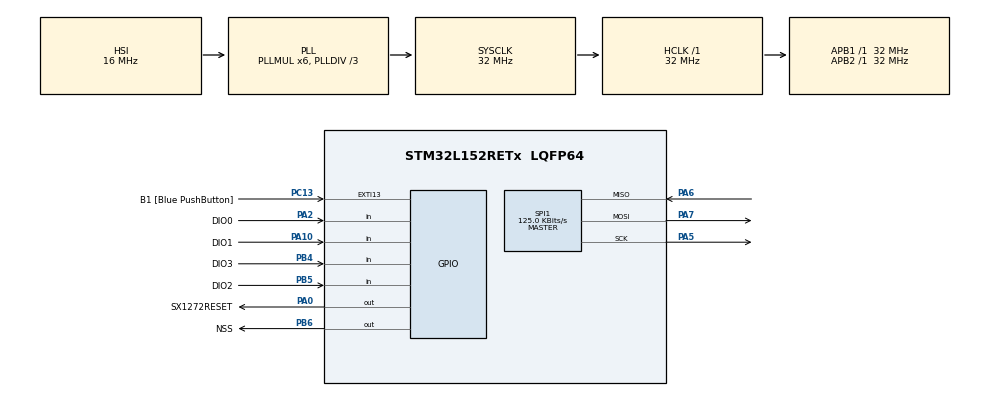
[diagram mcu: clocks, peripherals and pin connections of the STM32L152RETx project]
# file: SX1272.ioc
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Mcu.Family=STM32L1
Mcu.Name=STM32L152RETx
Mcu.Package=LQFP64
NVIC.PriorityGroup=NVIC_PRIORITYGROUP_0
NVIC.TIM11_IRQn=true\:0\:0\:false\:false\:true\:true\:true
PA0-WKUP1.GPIO_Label=SX1272RESET
PA0-WKUP1.Signal=GPIO_Output
PA10.GPIO_Label=DIO1
PA10.Signal=GPIO_Input
PA13.GPIO_Label=TMS
PA13.Mode=Serial_Wire
PA13.Signal=SYS_JTMS-SWDIO
PA14.GPIO_Label=TCK
PA14.Mode=Serial_Wire
PA14.Signal=SYS_JTCK-SWCLK
PA2.GPIO_Label=DIO0
PA2.Signal=GPIO_Input
PA5.Mode=Full_Duplex_Master
PA5.Signal=SPI1_SCK
PA6.Mode=Full_Duplex_Master
PA6.Signal=SPI1_MISO
PA7.Mode=Full_Duplex_Master
PA7.Signal=SPI1_MOSI
PB3.GPIO_Label=SWO
PB3.Signal=SYS_JTDO-TRACESWO
PB4.GPIO_Label=DIO3
PB4.Signal=GPIO_Input
PB5.GPIO_Label=DIO2
PB5.Signal=GPIO_Input
PB6.GPIO_Label=NSS
PB6.Signal=GPIO_Output
PC13-WKUP2.GPIO_Label=B1 [Blue PushButton]
PC13-WKUP2.Signal=GPXTI13
PC14-OSC32_IN.Mode=LSE-External-Oscillator
PC14-OSC32_IN.Signal=RCC_OSC32_IN
PC15-OSC32_OUT.Mode=LSE-External-Oscillator
PC15-OSC32_OUT.Signal=RCC_OSC32_OUT
PH0-OSC_IN.Mode=HSE-External-Clock-Source
PH0-OSC_IN.Signal=RCC_OSC_IN
PH1-OSC_OUT.Signal=RCC_OSC_OUT
ProjectManager.HeapSize=0x200
ProjectManager.StackSize=0x400
ProjectManager.TargetToolchain=SW4STM32
RCC.48MHZClocksFreq_Value=48000000
RCC.AHBFreq_Value=32000000
RCC.APB1Freq_Value=32000000
RCC.APB1TimFreq_Value=32000000
RCC.APB2Freq_Value=32000000
RCC.APB2TimFreq_Value=32000000
RCC.HCLKFreq_Value=32000000
RCC.HSE_VALUE=8000000
RCC.HSI_VALUE=16000000
RCC.MSI_VALUE=2097000
RCC.PLLDIV=RCC_PLL_DIV3
RCC.PLLMUL=RCC_PLL_MUL6
RCC.RTCClockSelectionVirtual=RCC_RTCCLKSOURCE_LSE
RCC.SYSCLKFreq_VALUE=32000000
RCC.SYSCLKSource=RCC_SYSCLKSOURCE_PLLCLK
RCC.USBOutput=48000000
RCC.VCOOutputFreq_Value=96000000
SPI1.BaudRatePrescaler=SPI_BAUDRATEPRESCALER_256
SPI1.CalculateBaudRate=125.0 KBits/s
SPI1.Direction=SPI_DIRECTION_2LINES
SPI1.Mode=SPI_MODE_MASTER
SPI1.VirtualType=VM_MASTER
TIM11.Period=1000
TIM11.Prescaler=32000
VP_TIM11_VS_ClockSourceINT.Mode=Internal
board=NUCLEO-L152RE

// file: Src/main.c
/* USER CODE BEGIN Header */
/**
  ******************************************************************************
  * @file           : main.c
  * @brief          : Main program body
  ******************************************************************************
  * @attention
  *
  * <h2><center>&copy; Copyright (c) 2020 STMicroelectronics.
  * All rights reserved.</center></h2>
  *
  * This software component is licensed by ST under BSD 3-Clause license,
  * the "License"; You may not use this file except in compliance with the
  * License. You may obtain a copy of the License at:
  *                        opensource.org/licenses/BSD-3-Clause
  *
  ******************************************************************************
  */
/* USER CODE END Header */

#include "main.h"

SPI_HandleTypeDef hspi1;

TIM_HandleTypeDef htim11;

/* USER CODE BEGIN PV */
	uint8_t Data[]={1,2,3,4,5,6,7,8,9,10};

/* USER CODE END PV */

void SystemClock_Config(void);
static void MX_GPIO_Init(void);
static void MX_SPI1_Init(void);
static void MX_TIM11_Init(void);

int main(void)
{

  /* MCU Configuration--------------------------------------------------------*/

  /* Reset of all peripherals, Initializes the Flash interface and the Systick. */
  HAL_Init();

  /* Configure the system clock */
  SystemClock_Config();

  /* Initialize all configured peripherals */
  MX_GPIO_Init();
  MX_SPI1_Init();
  MX_TIM11_Init();
  /* USER CODE BEGIN 2 */
  HAL_TIM_Base_Start(&htim11);
  HAL_TIM_Base_Start_IT(&htim11);

  HAL_GPIO_WritePin(NSS_GPIO_Port, NSS_Pin, GPIO_PIN_SET);
  SX1272Init();
  SX1272SetTxPacket(Data, 5);
  /* USER CODE END 2 */

  /* Infinite loop */
  /* USER CODE BEGIN WHILE */
  while (1)
  {
	  SX1272Process();
    /* USER CODE END WHILE */

  }
}

void SystemClock_Config(void)
{
  RCC_OscInitTypeDef RCC_OscInitStruct = {0};
  RCC_ClkInitTypeDef RCC_ClkInitStruct = {0};

  /** Configure the main internal regulator output voltage
  */
  __HAL_PWR_VOLTAGESCALING_CONFIG(PWR_REGULATOR_VOLTAGE_SCALE1);
  /** Initializes the CPU, AHB and APB busses clocks
  */
  RCC_OscInitStruct.OscillatorType = RCC_OSCILLATORTYPE_HSI;
  RCC_OscInitStruct.HSIState = RCC_HSI_ON;
  RCC_OscInitStruct.HSICalibrationValue = RCC_HSICALIBRATION_DEFAULT;
  RCC_OscInitStruct.PLL.PLLState = RCC_PLL_ON;
  RCC_OscInitStruct.PLL.PLLSource = RCC_PLLSOURCE_HSI;
  RCC_OscInitStruct.PLL.PLLMUL = RCC_PLL_MUL6;
  RCC_OscInitStruct.PLL.PLLDIV = RCC_PLL_DIV3;
  if (HAL_RCC_OscConfig(&RCC_OscInitStruct) != HAL_OK)
  {
    Error_Handler();
  }
  /** Initializes the CPU, AHB and APB busses clocks
  */
  RCC_ClkInitStruct.ClockType = RCC_CLOCKTYPE_HCLK|RCC_CLOCKTYPE_SYSCLK
                              |RCC_CLOCKTYPE_PCLK1|RCC_CLOCKTYPE_PCLK2;
  RCC_ClkInitStruct.SYSCLKSource = RCC_SYSCLKSOURCE_PLLCLK;
  RCC_ClkInitStruct.AHBCLKDivider = RCC_SYSCLK_DIV1;
  RCC_ClkInitStruct.APB1CLKDivider = RCC_HCLK_DIV1;
  RCC_ClkInitStruct.APB2CLKDivider = RCC_HCLK_DIV1;

  if (HAL_RCC_ClockConfig(&RCC_ClkInitStruct, FLASH_LATENCY_1) != HAL_OK)
  {
    Error_Handler();
  }
}

static void MX_SPI1_Init(void)
{

  /* SPI1 parameter configuration*/
  hspi1.Instance = SPI1;
  hspi1.Init.Mode = SPI_MODE_MASTER;
  hspi1.Init.Direction = SPI_DIRECTION_2LINES;
  hspi1.Init.DataSize = SPI_DATASIZE_8BIT;
  hspi1.Init.CLKPolarity = SPI_POLARITY_LOW;
  hspi1.Init.CLKPhase = SPI_PHASE_1EDGE;
  hspi1.Init.NSS = SPI_NSS_SOFT;
  hspi1.Init.BaudRatePrescaler = SPI_BAUDRATEPRESCALER_256;
  hspi1.Init.FirstBit = SPI_FIRSTBIT_MSB;
  hspi1.Init.TIMode = SPI_TIMODE_DISABLE;
  hspi1.Init.CRCCalculation = SPI_CRCCALCULATION_DISABLE;
  hspi1.Init.CRCPolynomial = 10;
  if (HAL_SPI_Init(&hspi1) != HAL_OK)
  {
    Error_Handler();
  }

}

static void MX_TIM11_Init(void)
{

  TIM_ClockConfigTypeDef sClockSourceConfig = {0};

  htim11.Instance = TIM11;
  htim11.Init.Prescaler = 32000;
  htim11.Init.CounterMode = TIM_COUNTERMODE_UP;
  htim11.Init.Period = 1000;
  htim11.Init.ClockDivision = TIM_CLOCKDIVISION_DIV1;
  htim11.Init.AutoReloadPreload = TIM_AUTORELOAD_PRELOAD_DISABLE;
  if (HAL_TIM_Base_Init(&htim11) != HAL_OK)
  {
    Error_Handler();
  }
  sClockSourceConfig.ClockSource = TIM_CLOCKSOURCE_INTERNAL;
  if (HAL_TIM_ConfigClockSource(&htim11, &sClockSourceConfig) != HAL_OK)
  {
    Error_Handler();
  }

}

static void MX_GPIO_Init(void)
{
  GPIO_InitTypeDef GPIO_InitStruct = {0};

  /* GPIO Ports Clock Enable */
  __HAL_RCC_GPIOC_CLK_ENABLE();
  __HAL_RCC_GPIOH_CLK_ENABLE();
  __HAL_RCC_GPIOA_CLK_ENABLE();
  __HAL_RCC_GPIOB_CLK_ENABLE();

  /*Configure GPIO pin Output Level */
  HAL_GPIO_WritePin(SX1272RESET_GPIO_Port, SX1272RESET_Pin, GPIO_PIN_RESET);

  /*Configure GPIO pin Output Level */
  HAL_GPIO_WritePin(NSS_GPIO_Port, NSS_Pin, GPIO_PIN_RESET);

  /*Configure GPIO pin : B1_Pin */
  GPIO_InitStruct.Pin = B1_Pin;
  GPIO_InitStruct.Mode = GPIO_MODE_IT_RISING;
  GPIO_InitStruct.Pull = GPIO_NOPULL;
  HAL_GPIO_Init(B1_GPIO_Port, &GPIO_InitStruct);

  /*Configure GPIO pin : SX1272RESET_Pin */
  GPIO_InitStruct.Pin = SX1272RESET_Pin;
  GPIO_InitStruct.Mode = GPIO_MODE_OUTPUT_PP;
  GPIO_InitStruct.Pull = GPIO_NOPULL;
  GPIO_InitStruct.Speed = GPIO_SPEED_FREQ_LOW;
  HAL_GPIO_Init(SX1272RESET_GPIO_Port, &GPIO_InitStruct);

  /*Configure GPIO pins : DIO0_Pin DIO1_Pin */
  GPIO_InitStruct.Pin = DIO0_Pin|DIO1_Pin;
  GPIO_InitStruct.Mode = GPIO_MODE_INPUT;
  GPIO_InitStruct.Pull = GPIO_NOPULL;
  HAL_GPIO_Init(GPIOA, &GPIO_InitStruct);

  /*Configure GPIO pins : DIO3_Pin DIO2_Pin */
  GPIO_InitStruct.Pin = DIO3_Pin|DIO2_Pin;
  GPIO_InitStruct.Mode = GPIO_MODE_INPUT;
  GPIO_InitStruct.Pull = GPIO_NOPULL;
  HAL_GPIO_Init(GPIOB, &GPIO_InitStruct);

  /*Configure GPIO pin : NSS_Pin */
  GPIO_InitStruct.Pin = NSS_Pin;
  GPIO_InitStruct.Mode = GPIO_MODE_OUTPUT_PP;
  GPIO_InitStruct.Pull = GPIO_NOPULL;
  GPIO_InitStruct.Speed = GPIO_SPEED_FREQ_LOW;
  HAL_GPIO_Init(NSS_GPIO_Port, &GPIO_InitStruct);

}

void Error_Handler(void)
{
}

/************************ (C) COPYRIGHT STMicroelectronics *****END OF FILE****/
